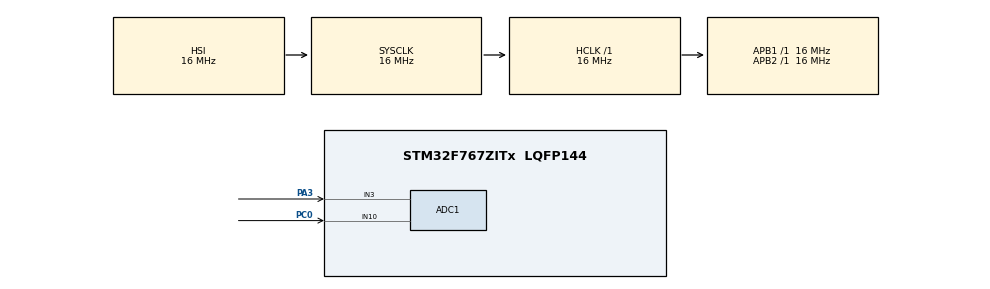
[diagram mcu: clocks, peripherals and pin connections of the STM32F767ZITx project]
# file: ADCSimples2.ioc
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ADC1.Channel-0\#ChannelRegularConversion=ADC_CHANNEL_3
ADC1.Channel-1\#ChannelRegularConversion=ADC_CHANNEL_10
ADC1.Channel-2\#ChannelRegularConversion=ADC_CHANNEL_TEMPSENSOR
ADC1.ContinuousConvMode=ENABLE
ADC1.NbrOfConversion=3
ADC1.NbrOfConversionFlag=1
ADC1.Rank-0\#ChannelRegularConversion=1
ADC1.Rank-1\#ChannelRegularConversion=2
ADC1.Rank-2\#ChannelRegularConversion=3
ADC1.SamplingTime-0\#ChannelRegularConversion=ADC_SAMPLETIME_144CYCLES
ADC1.SamplingTime-1\#ChannelRegularConversion=ADC_SAMPLETIME_144CYCLES
ADC1.SamplingTime-2\#ChannelRegularConversion=ADC_SAMPLETIME_144CYCLES
ADC1.ScanConvMode=ADC_SCAN_ENABLE
ADC1.master=1
Mcu.Family=STM32F7
Mcu.Name=STM32F767ZITx
Mcu.Package=LQFP144
NVIC.PriorityGroup=NVIC_PRIORITYGROUP_4
PA3.Signal=ADCx_IN3
PC0.Signal=ADCx_IN10
ProjectManager.HeapSize=0x200
ProjectManager.StackSize=0x400
ProjectManager.TargetToolchain=STM32CubeIDE
RCC.48MHZClocksFreq_Value=24000000
RCC.AHBFreq_Value=16000000
RCC.APB1Freq_Value=16000000
RCC.APB1TimFreq_Value=16000000
RCC.APB2Freq_Value=16000000
RCC.APB2TimFreq_Value=16000000
RCC.CortexFreq_Value=16000000
RCC.HCLKFreq_Value=16000000
RCC.HSE_VALUE=8000000
RCC.HSI_VALUE=16000000
RCC.PLLM=8
RCC.PLLMUL=RCC_PLL_MUL9
RCC.PLLN=96
RCC.PLLQ=4
RCC.PRESCALERUSB=RCC_USBCLKSOURCE_PLL_DIV1_5
RCC.SYSCLKFreq_VALUE=16000000
RCC.SYSCLKSourceVirtual=RCC_SYSCLKSOURCE_PLLCLK
RCC.USBFreq_Value=48000000
RCC.VCOOutputFreq_Value=192000000
SH.ADCx_IN10.0=ADC1_IN10,IN10
SH.ADCx_IN3.0=ADC1_IN3,IN3
VP_ADC1_TempSens_Input.Mode=IN-TempSens
board=NUCLEO-F767ZI

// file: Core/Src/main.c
/* USER CODE BEGIN Header */
/**
  ******************************************************************************
  * @file           : main.c
  * @brief          : Main program body
  ******************************************************************************
  * @attention
  *
  * Copyright (c) 2023 STMicroelectronics.
  * All rights reserved.
  *
  * This software is licensed under terms that can be found in the LICENSE file
  * in the root directory of this software component.
  * If no LICENSE file comes with this software, it is provided AS-IS.
  *
  ******************************************************************************
  */
/* USER CODE END Header */
#include "main.h"

/* USER CODE BEGIN Includes */
float adc[2];
float temp, vsense;

/* USER CODE END Includes */

ADC_HandleTypeDef hadc1;

void SystemClock_Config(void);
static void MX_GPIO_Init(void);
static void MX_ADC1_Init(void);

int main(void)
{

  /* MCU Configuration--------------------------------------------------------*/

  /* Reset of all peripherals, Initializes the Flash interface and the Systick. */
  HAL_Init();

  /* Configure the system clock */
  SystemClock_Config();

  /* Initialize all configured peripherals */
  MX_GPIO_Init();
  MX_ADC1_Init();

  /* Infinite loop */
  while (1)
  {

    /* USER CODE BEGIN 3 */

	  HAL_ADC_Start(&hadc1); //Inicialização do ADC

	  //Leitura da primeira entrada analógica
	  HAL_ADC_PollForConversion(&hadc1, 100);
	  adc[0] = HAL_ADC_GetValue(&hadc1);
	  adc[0] = (3.3/4095)*HAL_ADC_GetValue(&hadc1);

	  //Leitura da segunda entrada analógica
	  HAL_ADC_PollForConversion(&hadc1, 100);
	  adc[1] = HAL_ADC_GetValue(&hadc1);
	  adc[1] = (3.3/4095)*HAL_ADC_GetValue(&hadc1);

	  //Leitura da temperatura interna
	  HAL_ADC_PollForConversion(&hadc1, 100);
	  vsense = (3.3/4095)*HAL_ADC_GetValue(&hadc1);
	  temp = ((vsense-0.76)/0.0025)+25;

	  HAL_Delay(500);

	  HAL_ADC_Stop(&hadc1); //Finaliza a leitura analógica
  }
  /* USER CODE END 3 */
}

void SystemClock_Config(void)
{
  RCC_OscInitTypeDef RCC_OscInitStruct = {0};
  RCC_ClkInitTypeDef RCC_ClkInitStruct = {0};

  /** Configure the main internal regulator output voltage
  */
  __HAL_RCC_PWR_CLK_ENABLE();
  __HAL_PWR_VOLTAGESCALING_CONFIG(PWR_REGULATOR_VOLTAGE_SCALE3);

  /** Initializes the RCC Oscillators according to the specified parameters
  * in the RCC_OscInitTypeDef structure.
  */
  RCC_OscInitStruct.OscillatorType = RCC_OSCILLATORTYPE_HSI;
  RCC_OscInitStruct.HSIState = RCC_HSI_ON;
  RCC_OscInitStruct.HSICalibrationValue = RCC_HSICALIBRATION_DEFAULT;
  RCC_OscInitStruct.PLL.PLLState = RCC_PLL_NONE;
  if (HAL_RCC_OscConfig(&RCC_OscInitStruct) != HAL_OK)
  {
    Error_Handler();
  }

  /** Initializes the CPU, AHB and APB buses clocks
  */
  RCC_ClkInitStruct.ClockType = RCC_CLOCKTYPE_HCLK|RCC_CLOCKTYPE_SYSCLK
                              |RCC_CLOCKTYPE_PCLK1|RCC_CLOCKTYPE_PCLK2;
  RCC_ClkInitStruct.SYSCLKSource = RCC_SYSCLKSOURCE_HSI;
  RCC_ClkInitStruct.AHBCLKDivider = RCC_SYSCLK_DIV1;
  RCC_ClkInitStruct.APB1CLKDivider = RCC_HCLK_DIV1;
  RCC_ClkInitStruct.APB2CLKDivider = RCC_HCLK_DIV1;

  if (HAL_RCC_ClockConfig(&RCC_ClkInitStruct, FLASH_LATENCY_0) != HAL_OK)
  {
    Error_Handler();
  }
}

static void MX_ADC1_Init(void)
{

  ADC_ChannelConfTypeDef sConfig = {0};

  /** Configure the global features of the ADC (Clock, Resolution, Data Alignment and number of conversion)
  */
  hadc1.Instance = ADC1;
  hadc1.Init.ClockPrescaler = ADC_CLOCK_SYNC_PCLK_DIV2;
  hadc1.Init.Resolution = ADC_RESOLUTION_12B;
  hadc1.Init.ScanConvMode = ADC_SCAN_ENABLE;
  hadc1.Init.ContinuousConvMode = ENABLE;
  hadc1.Init.DiscontinuousConvMode = DISABLE;
  hadc1.Init.ExternalTrigConvEdge = ADC_EXTERNALTRIGCONVEDGE_NONE;
  hadc1.Init.ExternalTrigConv = ADC_SOFTWARE_START;
  hadc1.Init.DataAlign = ADC_DATAALIGN_RIGHT;
  hadc1.Init.NbrOfConversion = 3;
  hadc1.Init.DMAContinuousRequests = DISABLE;
  hadc1.Init.EOCSelection = ADC_EOC_SINGLE_CONV;
  if (HAL_ADC_Init(&hadc1) != HAL_OK)
  {
    Error_Handler();
  }

  /** Configure for the selected ADC regular channel its corresponding rank in the sequencer and its sample time.
  */
  sConfig.Channel = ADC_CHANNEL_3;
  sConfig.Rank = ADC_REGULAR_RANK_1;
  sConfig.SamplingTime = ADC_SAMPLETIME_144CYCLES;
  if (HAL_ADC_ConfigChannel(&hadc1, &sConfig) != HAL_OK)
  {
    Error_Handler();
  }

  /** Configure for the selected ADC regular channel its corresponding rank in the sequencer and its sample time.
  */
  sConfig.Channel = ADC_CHANNEL_10;
  sConfig.Rank = ADC_REGULAR_RANK_2;
  if (HAL_ADC_ConfigChannel(&hadc1, &sConfig) != HAL_OK)
  {
    Error_Handler();
  }

  /** Configure for the selected ADC regular channel its corresponding rank in the sequencer and its sample time.
  */
  sConfig.Channel = ADC_CHANNEL_TEMPSENSOR;
  sConfig.Rank = ADC_REGULAR_RANK_3;
  if (HAL_ADC_ConfigChannel(&hadc1, &sConfig) != HAL_OK)
  {
    Error_Handler();
  }

}

static void MX_GPIO_Init(void)
{

  /* GPIO Ports Clock Enable */
  __HAL_RCC_GPIOC_CLK_ENABLE();
  __HAL_RCC_GPIOA_CLK_ENABLE();

}

void Error_Handler(void)
{
  __disable_irq();
  while (1)
  {
  }
}
